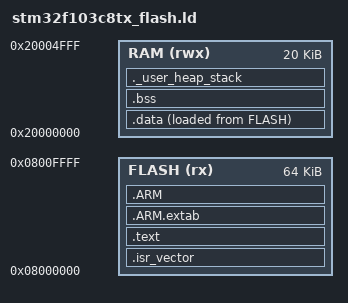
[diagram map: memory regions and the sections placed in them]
/*
 * stm32f103c8tx_flash.ld
 * Linker script for STM32F103C8T6 (Blue Pill)
 *
 * Flash : 0x08000000 — 64KB
 * SRAM  : 0x20000000 — 20KB
 */

ENTRY(Reset_Handler)

_estack = 0x20005000;    /* End of SRAM = start of stack (20KB = 0x5000) */

MEMORY
{
  FLASH (rx)  : ORIGIN = 0x08000000, LENGTH = 64K
  RAM   (rwx) : ORIGIN = 0x20000000, LENGTH = 20K
}

SECTIONS
{
  /* --------------------------------------------------------
   * Vector table and code go into Flash
   * -------------------------------------------------------- */
  .isr_vector :
  {
    . = ALIGN(4);
    KEEP(*(.isr_vector))
    . = ALIGN(4);
  } >FLASH

  .text :
  {
    . = ALIGN(4);
    *(.text)
    *(.text*)
    *(.rodata)
    *(.rodata*)
    KEEP(*(.init))
    KEEP(*(.fini))
    . = ALIGN(4);
    _etext = .;
  } >FLASH

  /* ARM exception handling tables */
  .ARM.extab :
  {
    *(.ARM.extab* .gnu.linkonce.armextab.*)
  } >FLASH

  .ARM :
  {
    __exidx_start = .;
    *(.ARM.exidx*)
    __exidx_end = .;
  } >FLASH

  /* --------------------------------------------------------
   * Initialized data — lives in Flash, copied to SRAM at boot
   * -------------------------------------------------------- */
  _sidata = LOADADDR(.data);

  .data :
  {
    . = ALIGN(4);
    _sdata = .;
    *(.data)
    *(.data*)
    . = ALIGN(4);
    _edata = .;
  } >RAM AT>FLASH

  /* --------------------------------------------------------
   * Zero-initialized data — stays in SRAM, zeroed at boot
   * -------------------------------------------------------- */
  .bss :
  {
    . = ALIGN(4);
    _sbss = .;
    __bss_start__ = _sbss;
    *(.bss)
    *(.bss*)
    *(COMMON)
    . = ALIGN(4);
    _ebss = .;
    __bss_end__ = _ebss;
  } >RAM

  /* --------------------------------------------------------
   * Stack and Heap in SRAM
   * -------------------------------------------------------- */
  ._user_heap_stack :
  {
    . = ALIGN(8);
    PROVIDE ( end = . );
    PROVIDE ( _end = . );
    . = . + 0x200;    /* Heap:  512 bytes */
    . = . + 0x400;    /* Stack: 1024 bytes */
    . = ALIGN(8);
  } >RAM

  /DISCARD/ :
  {
    libc.a ( * )
    libm.a ( * )
    libgcc.a ( * )
  }

  .ARM.attributes 0 :
  {
    *(.ARM.attributes)
  }
}
